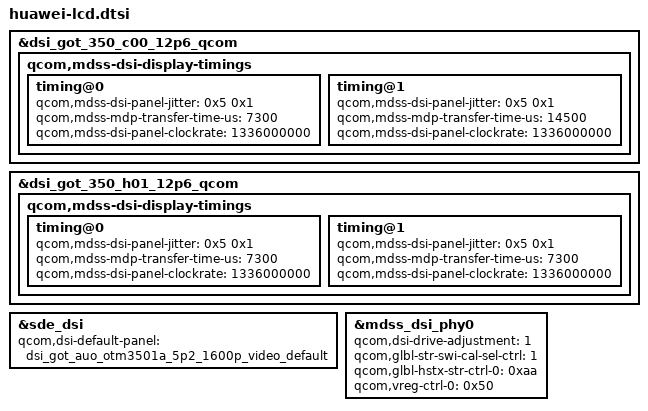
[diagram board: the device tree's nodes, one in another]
&dsi_got_350_c00_12p6_qcom {
        qcom,mdss-dsi-display-timings {
                timing@0 {
                        qcom,mdss-dsi-panel-jitter = <0x5 0x1>;
                        qcom,mdss-mdp-transfer-time-us = <7300>;
                        qcom,mdss-dsi-panel-clockrate = <1336000000>;
                };
                timing@1 {
                        qcom,mdss-dsi-panel-jitter = <0x5 0x1>;
                        qcom,mdss-mdp-transfer-time-us = <14500>;
                        qcom,mdss-dsi-panel-clockrate = <1336000000>;
                };
        };
};

&dsi_got_350_h01_12p6_qcom {
        qcom,mdss-dsi-display-timings {
                timing@0 {
                        qcom,mdss-dsi-panel-jitter = <0x5 0x1>;
                        qcom,mdss-mdp-transfer-time-us = <7300>;
                        qcom,mdss-dsi-panel-clockrate = <1336000000>;
                };
                timing@1 {
                        qcom,mdss-dsi-panel-jitter = <0x5 0x1>;
                        qcom,mdss-mdp-transfer-time-us = <7300>;
                        qcom,mdss-dsi-panel-clockrate = <1336000000>;
                };
        };
};

&sde_dsi {
	qcom,dsi-default-panel = <&dsi_got_auo_otm3501a_5p2_1600p_video_default>;
};

&mdss_dsi_phy0 {
	qcom,dsi-drive-adjustment = <1>;
	qcom,glbl-str-swi-cal-sel-ctrl = <1>;
	qcom,glbl-hstx-str-ctrl-0 = <0xaa>;
	qcom,vreg-ctrl-0 = <0x50>;
};
